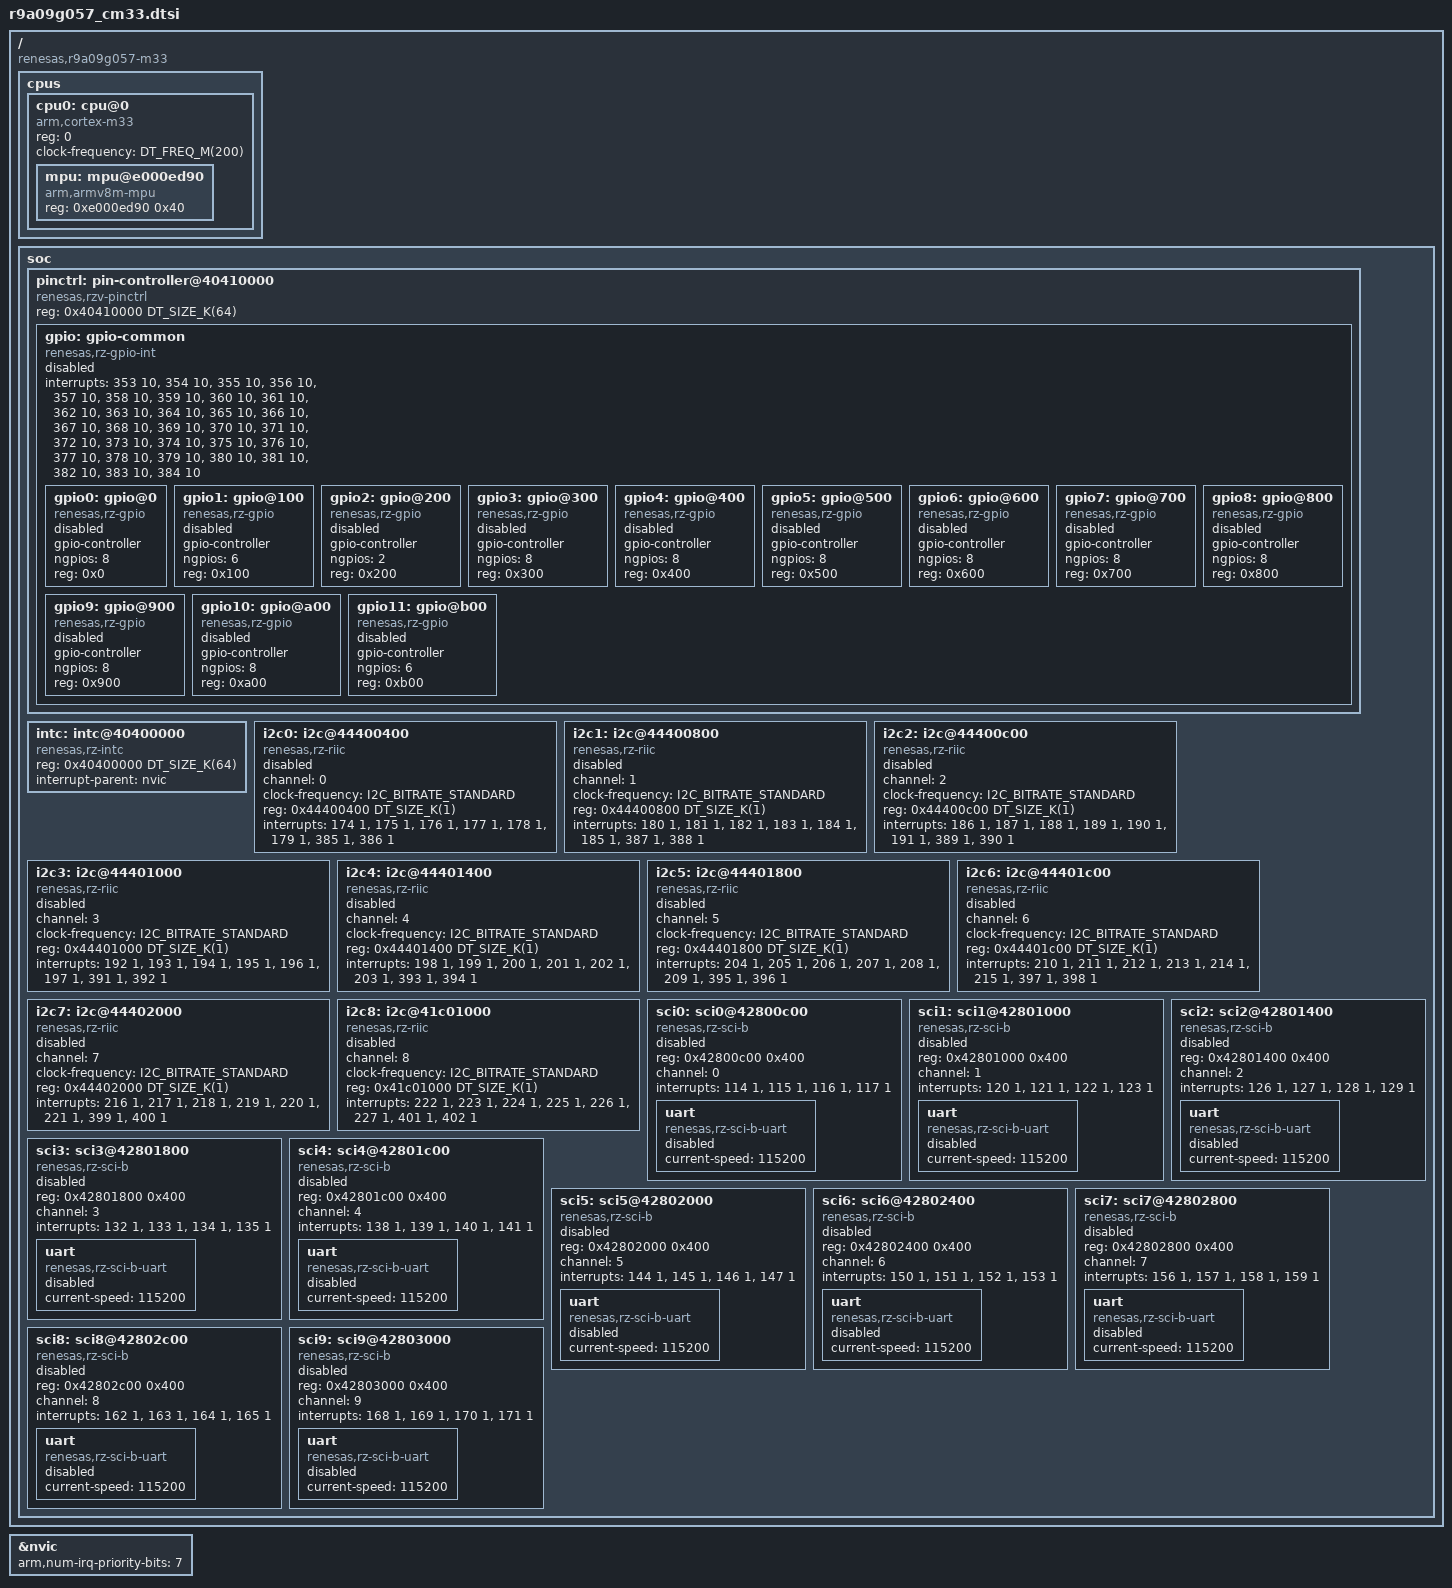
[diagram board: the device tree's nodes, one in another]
/*
 * Copyright (c) 2025 Renesas Electronics Corporation
 * SPDX-License-Identifier: Apache-2.0
 */

#include <arm/armv8-m.dtsi>
#include <mem.h>
#include <freq.h>
#include <zephyr/dt-bindings/i2c/i2c.h>

/ {
	compatible = "renesas,r9a09g057-m33";
	#address-cells = <1>;
	#size-cells = <1>;

	cpus {
		#address-cells = <1>;
		#size-cells = <0>;

		cpu0: cpu@0 {
			device_type = "cpu";
			compatible = "arm,cortex-m33";
			reg = <0>;
			clock-frequency = <DT_FREQ_M(200)>;
			#address-cells = <1>;
			#size-cells = <1>;

			mpu: mpu@e000ed90 {
				compatible = "arm,armv8m-mpu";
				reg = <0xe000ed90 0x40>;
			};
		};
	};

	soc {
		pinctrl: pin-controller@40410000 {
			compatible = "renesas,rzv-pinctrl";
			reg = <0x40410000 DT_SIZE_K(64)>;
			reg-names = "pinctrl";

			gpio: gpio-common {
				compatible = "renesas,rz-gpio-int";
				interrupts = <353 10>, <354 10>, <355 10>, <356 10>,
					     <357 10>, <358 10>, <359 10>, <360 10>,
					     <361 10>, <362 10>, <363 10>, <364 10>,
					     <365 10>, <366 10>, <367 10>, <368 10>,
					     <369 10>, <370 10>, <371 10>, <372 10>,
					     <373 10>, <374 10>, <375 10>, <376 10>,
					     <377 10>, <378 10>, <379 10>, <380 10>,
					     <381 10>, <382 10>, <383 10>, <384 10>;
				#address-cells = <1>;
				#size-cells = <0>;
				status = "disabled";

				gpio0: gpio@0 {
					compatible = "renesas,rz-gpio";
					gpio-controller;
					#gpio-cells = <2>;
					ngpios = <8>;
					reg = <0x0>;
					status = "disabled";
				};

				gpio1: gpio@100 {
					compatible = "renesas,rz-gpio";
					gpio-controller;
					#gpio-cells = <2>;
					ngpios = <6>;
					reg = <0x100>;
					status = "disabled";
				};

				gpio2: gpio@200 {
					compatible = "renesas,rz-gpio";
					gpio-controller;
					#gpio-cells = <2>;
					ngpios = <2>;
					reg = <0x200>;
					status = "disabled";
				};

				gpio3: gpio@300 {
					compatible = "renesas,rz-gpio";
					gpio-controller;
					#gpio-cells = <2>;
					ngpios = <8>;
					reg = <0x300>;
					status = "disabled";
				};

				gpio4: gpio@400 {
					compatible = "renesas,rz-gpio";
					gpio-controller;
					#gpio-cells = <2>;
					ngpios = <8>;
					reg = <0x400>;
					status = "disabled";
				};

				gpio5: gpio@500 {
					compatible = "renesas,rz-gpio";
					gpio-controller;
					#gpio-cells = <2>;
					ngpios = <8>;
					reg = <0x500>;
					status = "disabled";
				};

				gpio6: gpio@600 {
					compatible = "renesas,rz-gpio";
					gpio-controller;
					#gpio-cells = <2>;
					ngpios = <8>;
					reg = <0x600>;
					status = "disabled";
				};

				gpio7: gpio@700 {
					compatible = "renesas,rz-gpio";
					gpio-controller;
					#gpio-cells = <2>;
					ngpios = <8>;
					reg = <0x700>;
					status = "disabled";
				};

				gpio8: gpio@800 {
					compatible = "renesas,rz-gpio";
					gpio-controller;
					#gpio-cells = <2>;
					ngpios = <8>;
					reg = <0x800>;
					status = "disabled";
				};

				gpio9: gpio@900 {
					compatible = "renesas,rz-gpio";
					gpio-controller;
					#gpio-cells = <2>;
					ngpios = <8>;
					reg = <0x900>;
					status = "disabled";
				};

				gpio10: gpio@a00 {
					compatible = "renesas,rz-gpio";
					gpio-controller;
					#gpio-cells = <2>;
					ngpios = <8>;
					reg = <0xa00>;
					status = "disabled";
				};

				gpio11: gpio@b00 {
					compatible = "renesas,rz-gpio";
					gpio-controller;
					#gpio-cells = <2>;
					ngpios = <6>;
					reg = <0xb00>;
					status = "disabled";
				};
			};
		};

		intc: intc@40400000 {
			compatible = "renesas,rz-intc";
			reg = <0x40400000 DT_SIZE_K(64)>;
			#address-cells = <1>;
			#size-cells = <0>;
			interrupt-parent = <&nvic>;
		};

		i2c0: i2c@44400400 {
			compatible = "renesas,rz-riic";
			channel = <0>;
			clock-frequency = <I2C_BITRATE_STANDARD>;
			#address-cells = <1>;
			#size-cells = <0>;
			reg = <0x44400400 DT_SIZE_K(1)>;
			interrupts = <174 1>, <175 1>, <176 1>, <177 1>,
				     <178 1>, <179 1>, <385 1>, <386 1>;
			interrupt-names = "tei", "naki", "spi", "sti", "ali", "tmoi", "txi", "rxi";
			status = "disabled";
		};

		i2c1: i2c@44400800 {
			compatible = "renesas,rz-riic";
			channel = <1>;
			clock-frequency = <I2C_BITRATE_STANDARD>;
			#address-cells = <1>;
			#size-cells = <0>;
			reg = <0x44400800 DT_SIZE_K(1)>;
			interrupts = <180 1>, <181 1>, <182 1>, <183 1>,
				     <184 1>, <185 1>, <387 1>, <388 1>;
			interrupt-names = "tei", "naki", "spi", "sti", "ali", "tmoi", "txi", "rxi";
			status = "disabled";
		};

		i2c2: i2c@44400c00 {
			compatible = "renesas,rz-riic";
			channel = <2>;
			clock-frequency = <I2C_BITRATE_STANDARD>;
			#address-cells = <1>;
			#size-cells = <0>;
			reg = <0x44400c00 DT_SIZE_K(1)>;
			interrupts = <186 1>, <187 1>, <188 1>, <189 1>,
				     <190 1>, <191 1>, <389 1>, <390 1>;
			interrupt-names = "tei", "naki", "spi", "sti", "ali", "tmoi", "txi", "rxi";
			status = "disabled";
		};

		i2c3: i2c@44401000 {
			compatible = "renesas,rz-riic";
			channel = <3>;
			clock-frequency = <I2C_BITRATE_STANDARD>;
			#address-cells = <1>;
			#size-cells = <0>;
			reg = <0x44401000 DT_SIZE_K(1)>;
			interrupts = <192 1>, <193 1>, <194 1>, <195 1>,
				     <196 1>, <197 1>, <391 1>, <392 1>;
			interrupt-names = "tei", "naki", "spi", "sti", "ali", "tmoi", "txi", "rxi";
			status = "disabled";
		};

		i2c4: i2c@44401400 {
			compatible = "renesas,rz-riic";
			channel = <4>;
			clock-frequency = <I2C_BITRATE_STANDARD>;
			#address-cells = <1>;
			#size-cells = <0>;
			reg = <0x44401400 DT_SIZE_K(1)>;
			interrupts = <198 1>, <199 1>, <200 1>, <201 1>,
				     <202 1>, <203 1>, <393 1>, <394 1>;
			interrupt-names = "tei", "naki", "spi", "sti", "ali", "tmoi", "txi", "rxi";
			status = "disabled";
		};

		i2c5: i2c@44401800 {
			compatible = "renesas,rz-riic";
			channel = <5>;
			clock-frequency = <I2C_BITRATE_STANDARD>;
			#address-cells = <1>;
			#size-cells = <0>;
			reg = <0x44401800 DT_SIZE_K(1)>;
			interrupts = <204 1>, <205 1>, <206 1>, <207 1>,
				     <208 1>, <209 1>, <395 1>, <396 1>;
			interrupt-names = "tei", "naki", "spi", "sti", "ali", "tmoi", "txi", "rxi";
			status = "disabled";
		};

		i2c6: i2c@44401c00 {
			compatible = "renesas,rz-riic";
			channel = <6>;
			clock-frequency = <I2C_BITRATE_STANDARD>;
			#address-cells = <1>;
			#size-cells = <0>;
			reg = <0x44401c00 DT_SIZE_K(1)>;
			interrupts = <210 1>, <211 1>, <212 1>, <213 1>,
				     <214 1>, <215 1>, <397 1>, <398 1>;
			interrupt-names = "tei", "naki", "spi", "sti", "ali", "tmoi", "txi", "rxi";
			status = "disabled";
		};

		i2c7: i2c@44402000 {
			compatible = "renesas,rz-riic";
			channel = <7>;
			clock-frequency = <I2C_BITRATE_STANDARD>;
			#address-cells = <1>;
			#size-cells = <0>;
			reg = <0x44402000 DT_SIZE_K(1)>;
			interrupts = <216 1>, <217 1>, <218 1>, <219 1>,
				     <220 1>, <221 1>, <399 1>, <400 1>;
			interrupt-names = "tei", "naki", "spi", "sti", "ali", "tmoi", "txi", "rxi";
			status = "disabled";
		};

		i2c8: i2c@41c01000 {
			compatible = "renesas,rz-riic";
			channel = <8>;
			clock-frequency = <I2C_BITRATE_STANDARD>;
			#address-cells = <1>;
			#size-cells = <0>;
			reg = <0x41c01000 DT_SIZE_K(1)>;
			interrupts = <222 1>, <223 1>, <224 1>, <225 1>,
				     <226 1>, <227 1>, <401 1>, <402 1>;
			interrupt-names = "tei", "naki", "spi", "sti", "ali", "tmoi", "txi", "rxi";
			status = "disabled";
		};

		sci0: sci0@42800c00 {
			compatible = "renesas,rz-sci-b";
			reg = <0x42800c00 0x400>;
			channel = <0>;
			interrupts = <114 1>, <115 1>, <116 1>, <117 1>;
			interrupt-names = "eri", "rxi", "txi", "tei";
			status = "disabled";

			uart {
				compatible = "renesas,rz-sci-b-uart";
				current-speed = <115200>;
				status = "disabled";
			};
		};

		sci1: sci1@42801000 {
			compatible = "renesas,rz-sci-b";
			reg = <0x42801000 0x400>;
			channel = <1>;
			interrupts = <120 1>, <121 1>, <122 1>, <123 1>;
			interrupt-names = "eri", "rxi", "txi", "tei";
			status = "disabled";

			uart {
				compatible = "renesas,rz-sci-b-uart";
				current-speed = <115200>;
				status = "disabled";
			};
		};

		sci2: sci2@42801400 {
			compatible = "renesas,rz-sci-b";
			reg = <0x42801400 0x400>;
			channel = <2>;
			interrupts = <126 1>, <127 1>, <128 1>, <129 1>;
			interrupt-names = "eri", "rxi", "txi", "tei";
			status = "disabled";

			uart {
				compatible = "renesas,rz-sci-b-uart";
				current-speed = <115200>;
				status = "disabled";
			};
		};

		sci3: sci3@42801800 {
			compatible = "renesas,rz-sci-b";
			reg = <0x42801800 0x400>;
			channel = <3>;
			interrupts = <132 1>, <133 1>, <134 1>, <135 1>;
			interrupt-names = "eri", "rxi", "txi", "tei";
			status = "disabled";

			uart {
				compatible = "renesas,rz-sci-b-uart";
				current-speed = <115200>;
				status = "disabled";
			};
		};

		sci4: sci4@42801c00 {
			compatible = "renesas,rz-sci-b";
			reg = <0x42801c00 0x400>;
			channel = <4>;
			interrupts = <138 1>, <139 1>, <140 1>, <141 1>;
			interrupt-names = "eri", "rxi", "txi", "tei";
			status = "disabled";

			uart {
				compatible = "renesas,rz-sci-b-uart";
				current-speed = <115200>;
				status = "disabled";
			};
		};

		sci5: sci5@42802000 {
			compatible = "renesas,rz-sci-b";
			reg = <0x42802000 0x400>;
			channel = <5>;
			interrupts = <144 1>, <145 1>, <146 1>, <147 1>;
			interrupt-names = "eri", "rxi", "txi", "tei";
			status = "disabled";

			uart {
				compatible = "renesas,rz-sci-b-uart";
				current-speed = <115200>;
				status = "disabled";
			};
		};

		sci6: sci6@42802400 {
			compatible = "renesas,rz-sci-b";
			reg = <0x42802400 0x400>;
			channel = <6>;
			interrupts = <150 1>, <151 1>, <152 1>, <153 1>;
			interrupt-names = "eri", "rxi", "txi", "tei";
			status = "disabled";

			uart {
				compatible = "renesas,rz-sci-b-uart";
				current-speed = <115200>;
				status = "disabled";
			};
		};

		sci7: sci7@42802800 {
			compatible = "renesas,rz-sci-b";
			reg = <0x42802800 0x400>;
			channel = <7>;
			interrupts = <156 1>, <157 1>, <158 1>, <159 1>;
			interrupt-names = "eri", "rxi", "txi", "tei";
			status = "disabled";

			uart {
				compatible = "renesas,rz-sci-b-uart";
				current-speed = <115200>;
				status = "disabled";
			};
		};

		sci8: sci8@42802c00 {
			compatible = "renesas,rz-sci-b";
			reg = <0x42802c00 0x400>;
			channel = <8>;
			interrupts = <162 1>, <163 1>, <164 1>, <165 1>;
			interrupt-names = "eri", "rxi", "txi", "tei";
			status = "disabled";

			uart {
				compatible = "renesas,rz-sci-b-uart";
				current-speed = <115200>;
				status = "disabled";
			};
		};

		sci9: sci9@42803000 {
			compatible = "renesas,rz-sci-b";
			reg = <0x42803000 0x400>;
			channel = <9>;
			interrupts = <168 1>, <169 1>, <170 1>, <171 1>;
			interrupt-names = "eri", "rxi", "txi", "tei";
			status = "disabled";

			uart {
				compatible = "renesas,rz-sci-b-uart";
				current-speed = <115200>;
				status = "disabled";
			};
		};
	};
};

&nvic {
	arm,num-irq-priority-bits = <7>;
};
